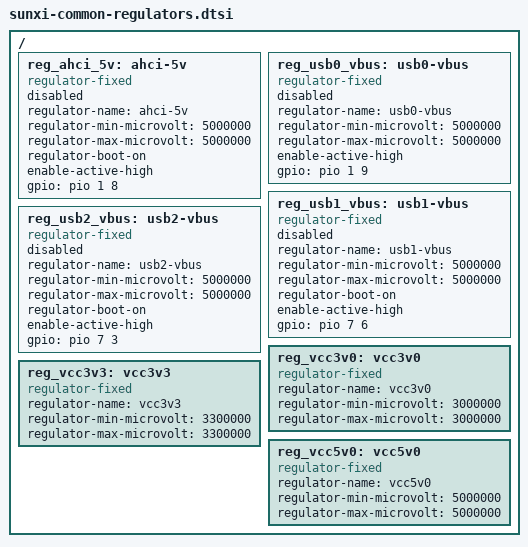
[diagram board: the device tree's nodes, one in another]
/*
 * sunxi boards common regulator (ahci target power supply, usb-vbus) code
 *
 * Copyright 2014 - Hans de Goede <hdegoede@redhat.com>
 *
 * This file is dual-licensed: you can use it either under the terms
 * of the GPL or the X11 license, at your option. Note that this dual
 * licensing only applies to this file, and not this project as a
 * whole.
 *
 *  a) This file is free software; you can redistribute it and/or
 *     modify it under the terms of the GNU General Public License as
 *     published by the Free Software Foundation; either version 2 of the
 *     License, or (at your option) any later version.
 *
 *     This file is distributed in the hope that it will be useful,
 *     but WITHOUT ANY WARRANTY; without even the implied warranty of
 *     MERCHANTABILITY or FITNESS FOR A PARTICULAR PURPOSE.  See the
 *     GNU General Public License for more details.
 *
 * Or, alternatively,
 *
 *  b) Permission is hereby granted, free of charge, to any person
 *     obtaining a copy of this software and associated documentation
 *     files (the "Software"), to deal in the Software without
 *     restriction, including without limitation the rights to use,
 *     copy, modify, merge, publish, distribute, sublicense, and/or
 *     sell copies of the Software, and to permit persons to whom the
 *     Software is furnished to do so, subject to the following
 *     conditions:
 *
 *     The above copyright notice and this permission notice shall be
 *     included in all copies or substantial portions of the Software.
 *
 *     THE SOFTWARE IS PROVIDED "AS IS", WITHOUT WARRANTY OF ANY KIND,
 *     EXPRESS OR IMPLIED, INCLUDING BUT NOT LIMITED TO THE WARRANTIES
 *     OF MERCHANTABILITY, FITNESS FOR A PARTICULAR PURPOSE AND
 *     NONINFRINGEMENT. IN NO EVENT SHALL THE AUTHORS OR COPYRIGHT
 *     HOLDERS BE LIABLE FOR ANY CLAIM, DAMAGES OR OTHER LIABILITY,
 *     WHETHER IN AN ACTION OF CONTRACT, TORT OR OTHERWISE, ARISING
 *     FROM, OUT OF OR IN CONNECTION WITH THE SOFTWARE OR THE USE OR
 *     OTHER DEALINGS IN THE SOFTWARE.
 */

#include <dt-bindings/gpio/gpio.h>

/ {
	reg_ahci_5v: ahci-5v {
		compatible = "regulator-fixed";
		regulator-name = "ahci-5v";
		regulator-min-microvolt = <5000000>;
		regulator-max-microvolt = <5000000>;
		regulator-boot-on;
		enable-active-high;
		gpio = <&pio 1 8 GPIO_ACTIVE_HIGH>;
		status = "disabled";
	};

	reg_usb0_vbus: usb0-vbus {
		compatible = "regulator-fixed";
		regulator-name = "usb0-vbus";
		regulator-min-microvolt = <5000000>;
		regulator-max-microvolt = <5000000>;
		enable-active-high;
		gpio = <&pio 1 9 GPIO_ACTIVE_HIGH>;
		status = "disabled";
	};

	reg_usb1_vbus: usb1-vbus {
		compatible = "regulator-fixed";
		regulator-name = "usb1-vbus";
		regulator-min-microvolt = <5000000>;
		regulator-max-microvolt = <5000000>;
		regulator-boot-on;
		enable-active-high;
		gpio = <&pio 7 6 GPIO_ACTIVE_HIGH>;
		status = "disabled";
	};

	reg_usb2_vbus: usb2-vbus {
		compatible = "regulator-fixed";
		regulator-name = "usb2-vbus";
		regulator-min-microvolt = <5000000>;
		regulator-max-microvolt = <5000000>;
		regulator-boot-on;
		enable-active-high;
		gpio = <&pio 7 3 GPIO_ACTIVE_HIGH>;
		status = "disabled";
	};

	reg_vcc3v0: vcc3v0 {
		compatible = "regulator-fixed";
		regulator-name = "vcc3v0";
		regulator-min-microvolt = <3000000>;
		regulator-max-microvolt = <3000000>;
	};

	reg_vcc3v3: vcc3v3 {
		compatible = "regulator-fixed";
		regulator-name = "vcc3v3";
		regulator-min-microvolt = <3300000>;
		regulator-max-microvolt = <3300000>;
	};

	reg_vcc5v0: vcc5v0 {
		compatible = "regulator-fixed";
		regulator-name = "vcc5v0";
		regulator-min-microvolt = <5000000>;
		regulator-max-microvolt = <5000000>;
	};
};
